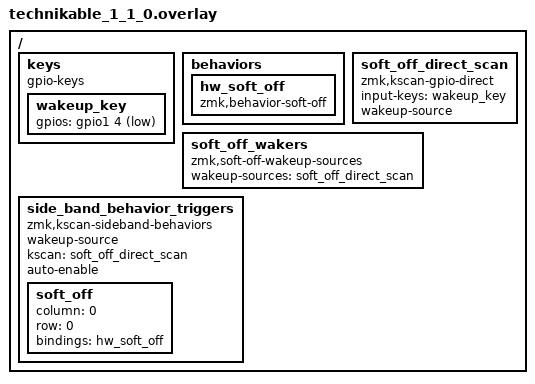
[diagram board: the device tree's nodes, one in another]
/ {
	keys {
		compatible = "gpio-keys";
		wakeup_key: wakeup_key {
			gpios = <&gpio1 4 (GPIO_ACTIVE_LOW | GPIO_PULL_UP)>;
		};
	};
	
	behaviors {
		hw_soft_off: hw_soft_off {
			compatible = "zmk,behavior-soft-off";
			#binding-cells = <0>;
		};
	};
	
	soft_off_direct_scan: soft_off_direct_scan {
		compatible = "zmk,kscan-gpio-direct";
		input-keys = <&wakeup_key>;
		wakeup-source;
	};

        soft_off_wakers {
		compatible = "zmk,soft-off-wakeup-sources";
		wakeup-sources = <&soft_off_direct_scan>;
	};

	side_band_behavior_triggers: side_band_behavior_triggers {
		compatible = "zmk,kscan-sideband-behaviors";
		wakeup-source;
		kscan = <&soft_off_direct_scan>;
		auto-enable;
		soft_off {
			column = <0>;
			row = <0>;
			bindings = <&hw_soft_off>;
		};
	};

};
